# STM32F410 register map
File version: 1.3
CPU: CM4 r0p1, little endian, MPU, FPU, 4 interrupt priority bits
Registers are 32-bit, read-write, reset 0x0 unless marked. A register's access mark holds for its fields unless they carry their own. Offsets are from the block's base; lines under a group give offsets from that group; [hi:lo] are bit positions; {n}, {i} and the like mark numbered series; 'fields as' and 'values as' point back to an identical list; <NAME> marks a mode.

## Memory map
0x40000C00 TIM5 size 0x400 — General-purpose-timers
0x40001000 TIM6 size 0x400 — Basic timers
0x40002400 LPTIM1 size 0x400 — Low power timer
0x40002800 RTC size 0x400 — Real-time clock
0x40002C00 WWDG size 0x400 — Window watchdog
0x40003000 IWDG size 0x400 — Independent watchdog
0x40003800 SPI2 size 0x400
0x40004400 USART2 size 0x400
0x40005400 I2C1 size 0x400
0x40005800 I2C2 size 0x400 — Inter-integrated circuit
0x40006000 I2C4 size 0x400 — Inter-integrated circuit
0x40007000 PWR size 0x400 — Power control
0x40007400 DAC size 0x400 — Digital-to-analog converter
0x40010000 TIM1 size 0x400 — Advanced-timers
0x40010400 TIM8 size 0x400
0x40011000 USART1 size 0x400 — Universal synchronous asynchronous receiver transmitter
0x40011400 USART6 size 0x400
0x40012000 ADC1 size 0x51 — Analog-to-digital converter
0x40012300 ADC_Common size 0x9 — ADC common registers
0x40013000 SPI1 size 0x400 — Serial peripheral interface
0x40013800 SYSCFG size 0x400 — System configuration controller
0x40013C00 EXTI size 0x400 — External interrupt/event controller
0x40014000 TIM9 size 0x400 — General purpose timers
0x40014800 TIM11 size 0x400 — General-purpose-timers
0x40015000 SPI5 size 0x400
0x40020000 GPIOA size 0x400 — General-purpose I/Os
0x40020400 GPIOB size 0x400 — General-purpose I/Os
0x40020800 GPIOC size 0x400
0x40021C00 GPIOH size 0x400 — General-purpose I/Os
0x40023000 CRC size 0x400 — Cryptographic processor
0x40023800 RCC size 0x400 — Reset and clock control
0x40023C00 FLASH size 0x400
0x40026000 DMA1 size 0x400
0x40026400 DMA2 size 0x400 — DMA controller
0x40080000 RNG size 0x400 — Random number generator
0xE000E008 SCB_ACTRL size 0x5 — System control block ACTLR
0xE000E010 STK size 0x11 — SysTick timer
0xE000E100 NVIC size 0x351 — Nested Vectored Interrupt Controller
0xE000ED00 SCB size 0x41 — System control block
0xE000ED88 FPU_CPACR size 0x5 — Floating point unit CPACR
0xE000ED90 MPU size 0x15 — Memory protection unit
0xE000EF00 NVIC_STIR size 0x5 — Nested vectored interrupt controller
0xE000EF34 FPU size 0xD — Floting point unit
0xE0042000 DBG size 0x400 — Debug support

## Interrupts
1 PVD (PWR) — PVD through EXTI line detection interrupt
2 TAMP_STAMP (EXTI) — Tamper and TimeStamp interrupts through the EXTI line
3 RTC_WKUP (RTC) — RTC Wakeup interrupt through the EXTI line
4 FLASH — FLASH global interrupt
5 RCC — RCC global interrupt
6 EXTI0 (EXTI) — EXTI Line0 interrupt
7 EXTI1 (EXTI) — EXTI Line1 interrupt
8 EXTI2 (EXTI) — EXTI Line2 interrupt
9 EXTI3 (EXTI) — EXTI Line3 interrupt
10 EXTI4 (EXTI) — EXTI Line4 interrupt
18 ADC (ADC1) — ADC1 global interrupt
23 EXTI9_5 (EXTI) — EXTI Line[9:5] interrupts
24 TIM1_BRK_TIM9 (TIM1) — TIM1 Break interrupt and TIM9 global interrupt
25 PWM1_UP (TIM1) — Timer1 Update interrupt
26 TIM1_TRG_COM_TIM11 (TIM1) — TIM1 Trigger and Commutation interrupts and TIM11 global interrupt
27 TIM1_CC (TIM1) — TIM1 Capture Compare interrupt
31 I2C1_EV (I2C1) — I2C1 event interrupt
32 I2C1_ER (I2C1) — I2C1 error interrupt
33 I2C2_EV (I2C2) — I2C2 event interrupt
34 I2C2_ER (I2C2) — I2C2 error interrupt
35 SPI1 — SPI1 global interrupt
36 SPI2 — SPI2 global interrupt
40 EXTI15_10 (EXTI) — EXTI Line[15:10] interrupts
41 RTC_Alarm (DMA1) — RTC Alarms (A and B) through EXTI line interrupt
54 TIM6_DAC1 (TIM6) — Timer6 and DAC1 global interrupt
80 RNG — RNG global interrupt
81 FPU — Floating point unit interrupt
95 I2C4_EV (I2C4) — I2C4 event interrupt
96 I2C4_ER (I2C4) — I2C2 error interrupt
97 LPTIM1 — LPTimer global interrupt

## ADC_Common — ADC common registers
Base 0x40012300
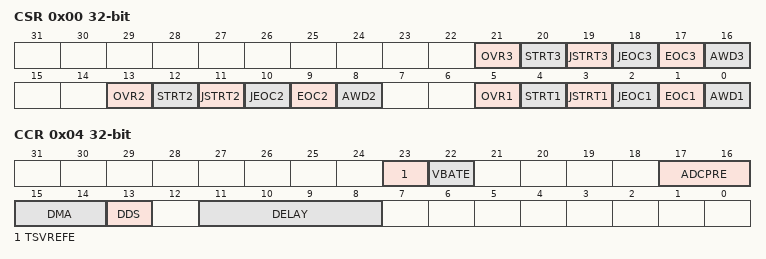
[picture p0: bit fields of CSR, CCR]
0x00 CSR ro — ADC Common status register
  [21] OVR3 — Overrun flag of ADC3
  [20] STRT3 — Regular channel Start flag of ADC 3
  [19] JSTRT3 — Injected channel Start flag of ADC 3
  [18] JEOC3 — Injected channel end of conversion of ADC 3
  [17] EOC3 — End of conversion of ADC 3
  [16] AWD3 — Analog watchdog flag of ADC 3
  [13] OVR2 — Overrun flag of ADC 2
  [12] STRT2 — Regular channel Start flag of ADC 2
  [11] JSTRT2 — Injected channel Start flag of ADC 2
  [10] JEOC2 — Injected channel end of conversion of ADC 2
  [9] EOC2 — End of conversion of ADC 2
  [8] AWD2 — Analog watchdog flag of ADC 2
  [5] OVR1 — Overrun flag of ADC 1
  [4] STRT1 — Regular channel Start flag of ADC 1
  [3] JSTRT1 — Injected channel Start flag of ADC 1
  [2] JEOC1 — Injected channel end of conversion of ADC 1
  [1] EOC1 — End of conversion of ADC 1
  [0] AWD1 — Analog watchdog flag of ADC 1
0x04 CCR — ADC common control register
  [23] TSVREFE — Temperature sensor and VREFINT enable
  [22] VBATE — VBAT enable
  [17:16] ADCPRE — ADC prescaler
  [15:14] DMA — Direct memory access mode for multi ADC mode
  [13] DDS — DMA disable selection for multi-ADC mode
  [11:8] DELAY — Delay between 2 sampling phases
